NS_ :

BS_:

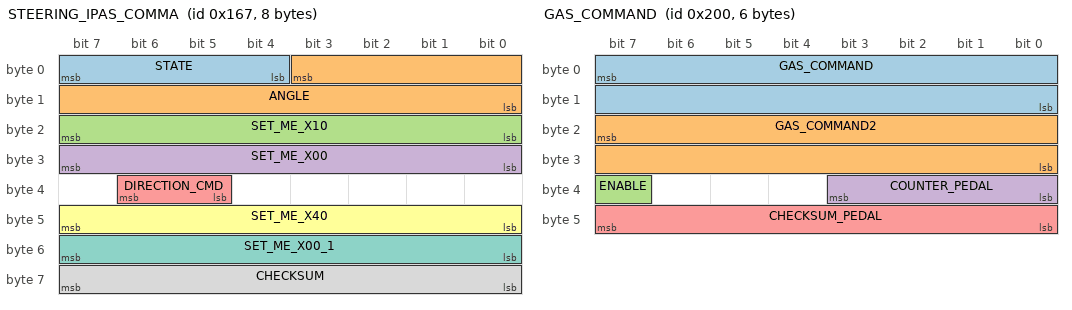
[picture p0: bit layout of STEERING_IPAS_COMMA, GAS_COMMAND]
BO_ 359 STEERING_IPAS_COMMA: 8 IPAS
 SG_ STATE : 7|4@0+ (1,0) [0|15] "" XXX
 SG_ ANGLE : 3|12@0- (1.5,0) [-510|510] "deg" XXX
 SG_ SET_ME_X10 : 23|8@0+ (1,0) [0|255] "" XXX
 SG_ SET_ME_X00 : 31|8@0+ (1,0) [0|255] "" XXX
 SG_ DIRECTION_CMD : 38|2@0+ (1,0) [0|3] "" XXX
 SG_ SET_ME_X40 : 47|8@0+ (1,0) [0|255] "" XXX
 SG_ SET_ME_X00_1 : 55|8@0+ (1,0) [0|255] "" XXX
 SG_ CHECKSUM : 63|8@0+ (1,0) [0|255] "" XXX

BO_ 512 GAS_COMMAND: 6 EON
 SG_ GAS_COMMAND : 7|16@0+ (0.159375,-75.555) [0|1] "" INTERCEPTOR
 SG_ GAS_COMMAND2 : 23|16@0+ (0.159375,-151.111) [0|1] "" INTERCEPTOR
 SG_ ENABLE : 39|1@0+ (1,0) [0|1] "" INTERCEPTOR
 SG_ COUNTER_PEDAL : 35|4@0+ (1,0) [0|15] "" INTERCEPTOR
 SG_ CHECKSUM_PEDAL : 47|8@0+ (1,0) [0|255] "" INTERCEPTOR

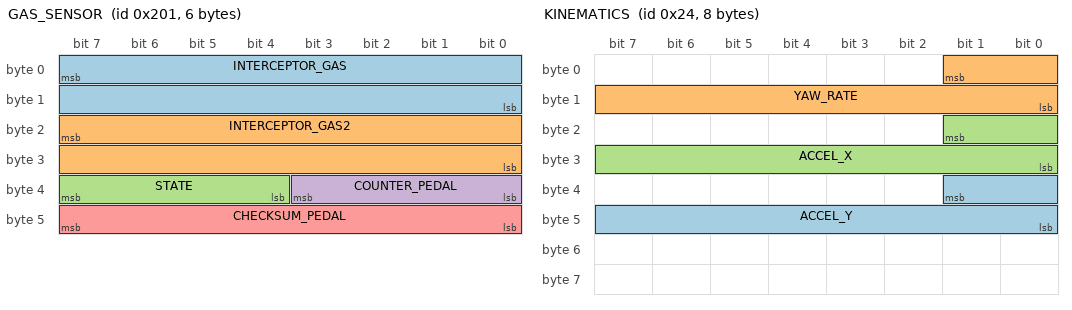
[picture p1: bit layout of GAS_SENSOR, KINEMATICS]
BO_ 513 GAS_SENSOR: 6 INTERCEPTOR
 SG_ INTERCEPTOR_GAS : 7|16@0+ (1,0) [0|1] "" EON
 SG_ INTERCEPTOR_GAS2 : 23|16@0+ (1,0) [0|1] "" EON
 SG_ STATE : 39|4@0+ (1,0) [0|15] "" EON
 SG_ COUNTER_PEDAL : 35|4@0+ (1,0) [0|15] "" EON
 SG_ CHECKSUM_PEDAL : 47|8@0+ (1,0) [0|255] "" EON

BO_ 35 SECONDARY_STEER_ANGLE: 8 XXX
 SG_ ZORRO_STEER : 7|24@0- (0.004901594652,0) [-500|500] "" XXX

BO_ 767 SDSU: 8 XXX
 SG_ FD_BUTTON : 7|1@0+ (1,0) [0|1] "" XXX

BO_ 36 KINEMATICS: 8 XXX
 SG_ ACCEL_Y : 33|10@0+ (0.03589,-18.375) [0|65535] "m/s^2" XXX
 SG_ YAW_RATE : 1|10@0+ (0.244,-125) [0|65535] "deg/s" XXX
 SG_ ACCEL_X : 17|10@0+ (0.03589,-18.375) [0|65535] "m/s^2" XXX

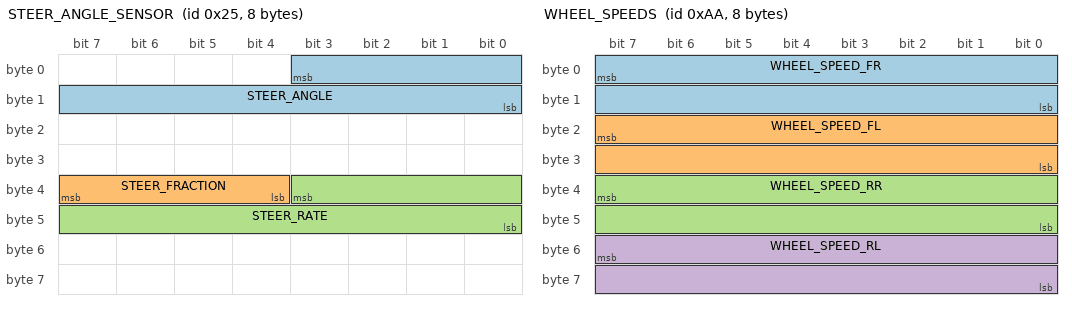
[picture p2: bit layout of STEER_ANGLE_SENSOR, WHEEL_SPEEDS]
BO_ 37 STEER_ANGLE_SENSOR: 8 XXX
 SG_ STEER_ANGLE : 3|12@0- (1.5,0) [-500|500] "deg" XXX
 SG_ STEER_FRACTION : 39|4@0- (0.1,0) [-0.7|0.7] "deg" XXX
 SG_ STEER_RATE : 35|12@0- (1,0) [-2000|2000] "deg/s" XXX

BO_ 166 BRAKE: 8 XXX
 SG_ BRAKE_AMOUNT : 7|8@0+ (1,0) [0|255] "" XXX
 SG_ BRAKE_PEDAL : 23|8@0+ (1,0) [0|255] "" XXX

BO_ 170 WHEEL_SPEEDS: 8 XXX
 SG_ WHEEL_SPEED_FR : 7|16@0+ (0.01,-67.67) [0|250] "km/h" XXX
 SG_ WHEEL_SPEED_FL : 23|16@0+ (0.01,-67.67) [0|250] "km/h" XXX
 SG_ WHEEL_SPEED_RR : 39|16@0+ (0.01,-67.67) [0|250] "km/h" XXX
 SG_ WHEEL_SPEED_RL : 55|16@0+ (0.01,-67.67) [0|250] "km/h" XXX

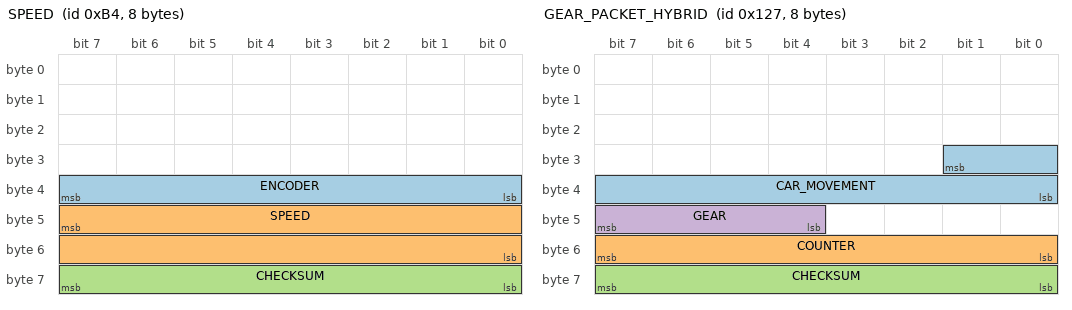
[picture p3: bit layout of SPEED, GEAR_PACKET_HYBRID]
BO_ 180 SPEED: 8 XXX
 SG_ ENCODER : 39|8@0+ (1,0) [0|255] "" XXX
 SG_ SPEED : 47|16@0+ (0.01,0) [0|250] "km/h" XXX
 SG_ CHECKSUM : 63|8@0+ (1,0) [0|255] "" XXX

BO_ 295 GEAR_PACKET_HYBRID: 8 XXX
 SG_ CAR_MOVEMENT : 25|10@0- (1,0) [0|255] "" XXX
 SG_ COUNTER : 55|8@0+ (1,0) [0|255] "" XXX
 SG_ CHECKSUM : 63|8@0+ (1,0) [0|255] "" XXX
 SG_ GEAR : 47|4@0+ (1,0) [0|15] "" XXX

BO_ 353 DSU_SPEED: 7 XXX
 SG_ FORWARD_SPEED : 15|16@0- (0.00390625,-30) [0|255] "km/h" XXX

BO_ 452 ENGINE_RPM: 8 CGW
 SG_ RPM : 7|16@0- (0.78125,0) [0|0] "rpm" SCS

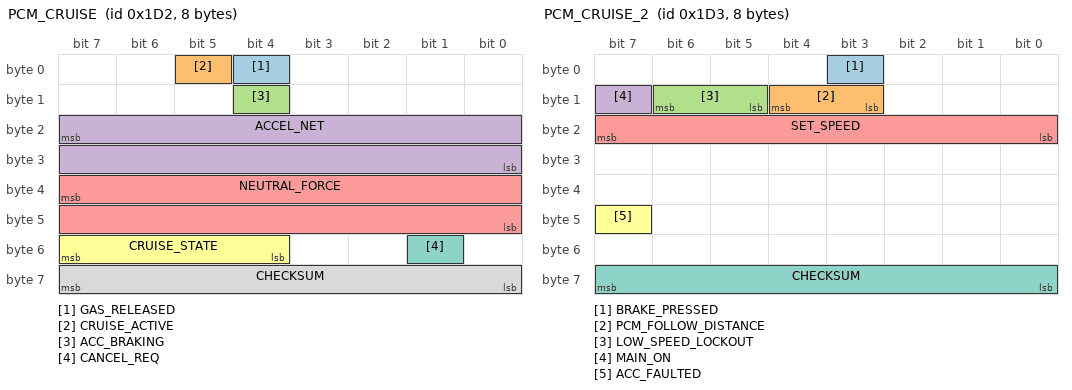
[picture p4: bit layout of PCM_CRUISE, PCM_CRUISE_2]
BO_ 466 PCM_CRUISE: 8 XXX
 SG_ GAS_RELEASED : 4|1@0+ (1,0) [0|1] "" XXX
 SG_ CRUISE_ACTIVE : 5|1@0+ (1,0) [0|1] "" XXX
 SG_ ACC_BRAKING : 12|1@0+ (1,0) [0|1] "" XXX
 SG_ ACCEL_NET : 23|16@0- (0.0009765625,0) [-20|20] "m/s^2" XXX
 SG_ NEUTRAL_FORCE : 39|16@0- (2,0) [-65536|65534] "N" XXX
 SG_ CRUISE_STATE : 55|4@0+ (1,0) [0|15] "" XXX
 SG_ CANCEL_REQ : 49|1@1+ (1,0) [0|1] "" XXX
 SG_ CHECKSUM : 63|8@0+ (1,0) [0|255] "" XXX

BO_ 467 PCM_CRUISE_2: 8 XXX
 SG_ BRAKE_PRESSED : 3|1@0+ (1,0) [0|1] "" XXX
 SG_ PCM_FOLLOW_DISTANCE : 12|2@0+ (1,0) [0|3] "" XXX
 SG_ LOW_SPEED_LOCKOUT : 14|2@0+ (1,0) [0|3] "" XXX
 SG_ MAIN_ON : 15|1@0+ (1,0) [0|1] "" XXX
 SG_ SET_SPEED : 23|8@0+ (1,0) [0|255] "km/h" XXX
 SG_ ACC_FAULTED : 47|1@0+ (1,0) [0|1] "" XXX
 SG_ CHECKSUM : 63|8@0+ (1,0) [0|255] "" XXX

BO_ 552 ACCELEROMETER: 8 XXX
 SG_ ACCEL_Z : 22|15@0- (1,0) [0|32767] "m/s^2" XXX
 SG_ ACCEL_X : 6|15@0- (0.001,0) [-20|20] "m/s^2" XXX

BO_ 560 BRAKE_2: 7 XXX
 SG_ BRAKE_PRESSED : 26|1@0+ (1,0) [0|1] "" XXX

BO_ 581 GAS_PEDAL_HYBRID: 8 XXX
 SG_ GAS_PEDAL : 23|8@0+ (0.005,0) [0|1] "" XXX

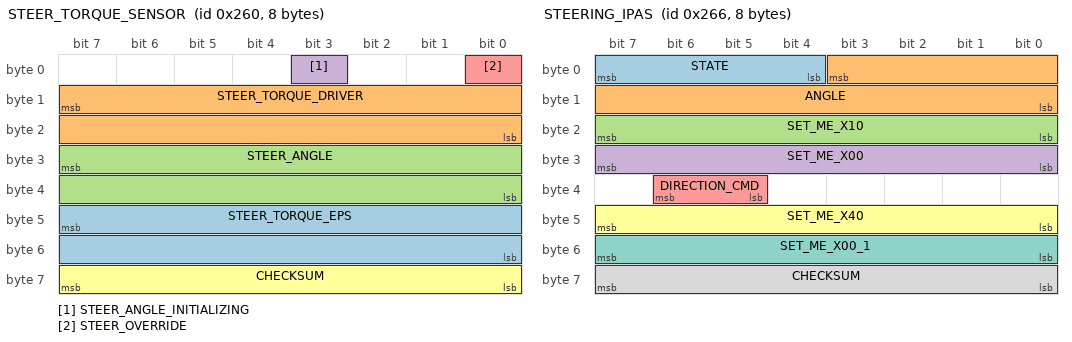
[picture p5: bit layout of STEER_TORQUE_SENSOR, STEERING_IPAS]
BO_ 608 STEER_TORQUE_SENSOR: 8 XXX
 SG_ STEER_TORQUE_EPS : 47|16@0- (1,0) [-32768|32767] "" XXX
 SG_ STEER_TORQUE_DRIVER : 15|16@0- (1,0) [-32768|32767] "" XXX
 SG_ STEER_ANGLE : 31|16@0- (0.0573,0) [-500|500] "" XXX
 SG_ STEER_ANGLE_INITIALIZING : 3|1@0+ (1,0) [0|1] "" XXX
 SG_ STEER_OVERRIDE : 0|1@0+ (1,0) [0|1] "" XXX
 SG_ CHECKSUM : 63|8@0+ (1,0) [0|255] "" XXX

BO_ 614 STEERING_IPAS: 8 IPAS
 SG_ STATE : 7|4@0+ (1,0) [0|15] "" XXX
 SG_ ANGLE : 3|12@0- (1.5,0) [-510|510] "deg" XXX
 SG_ SET_ME_X10 : 23|8@0+ (1,0) [0|255] "" XXX
 SG_ SET_ME_X00 : 31|8@0+ (1,0) [0|255] "" XXX
 SG_ DIRECTION_CMD : 38|2@0+ (1,0) [0|3] "" XXX
 SG_ SET_ME_X40 : 47|8@0+ (1,0) [0|255] "" XXX
 SG_ SET_ME_X00_1 : 55|8@0+ (1,0) [0|255] "" XXX
 SG_ CHECKSUM : 63|8@0+ (1,0) [0|255] "" XXX

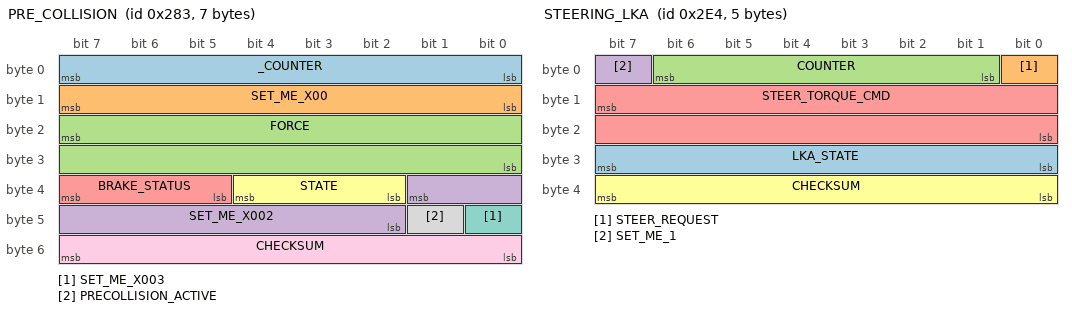
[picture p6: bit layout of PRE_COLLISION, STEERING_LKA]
BO_ 643 PRE_COLLISION: 7 DSU
 SG_ _COUNTER : 7|8@0+ (1,0) [0|255] "" XXX
 SG_ SET_ME_X00 : 15|8@0+ (1,0) [0|255] "" XXX
 SG_ FORCE : 23|16@0- (2,0) [0|255] "N" XXX
 SG_ SET_ME_X002 : 33|8@0+ (1,0) [0|3] "" XXX
 SG_ BRAKE_STATUS : 39|3@0+ (1,0) [0|255] "" XXX
 SG_ STATE : 36|3@0+ (1,0) [0|255] "" XXX
 SG_ SET_ME_X003 : 40|1@0+ (1,0) [0|1] "" XXX
 SG_ PRECOLLISION_ACTIVE : 41|1@0+ (1,0) [0|255] "" XXX
 SG_ CHECKSUM : 55|8@0+ (1,0) [0|255] "" XXX

BO_ 705 GAS_PEDAL: 8 XXX
 SG_ GAS_RELEASED : 3|1@0+ (1,0) [0|1] "" XXX
 SG_ GAS_PEDAL : 55|8@0+ (0.005,0) [0|1] "" XXX

BO_ 740 STEERING_LKA: 5 XXX
 SG_ LKA_STATE : 31|8@0+ (1,0) [0|255] "" XXX
 SG_ STEER_REQUEST : 0|1@0+ (1,0) [0|1] "" XXX
 SG_ COUNTER : 6|6@0+ (1,0) [0|63] "" XXX
 SG_ SET_ME_1 : 7|1@0+ (1,0) [0|1] "" XXX
 SG_ STEER_TORQUE_CMD : 15|16@0- (1,0) [0|65535] "" XXX
 SG_ CHECKSUM : 39|8@0+ (1,0) [0|255] "" XXX

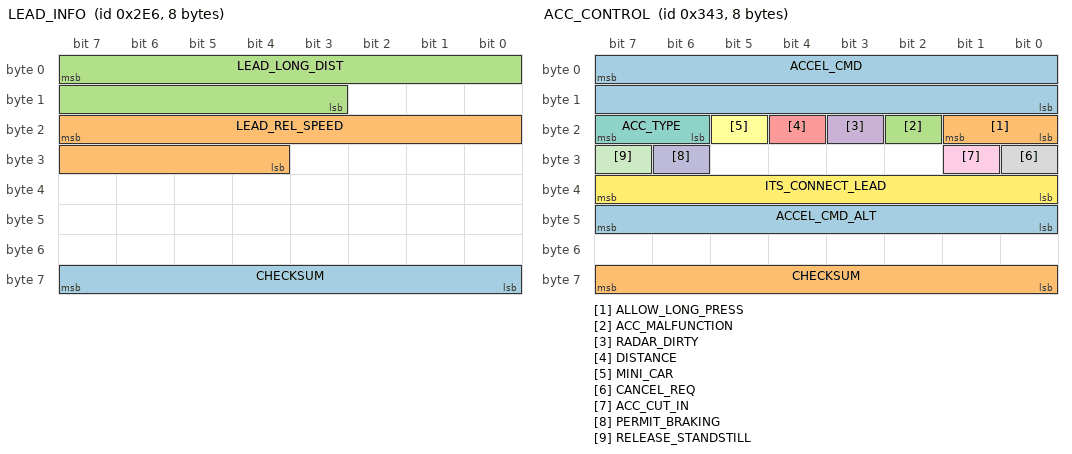
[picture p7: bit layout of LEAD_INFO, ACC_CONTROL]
BO_ 742 LEAD_INFO: 8 DSU
 SG_ CHECKSUM : 63|8@0+ (1,0) [0|255] "" HCU
 SG_ LEAD_REL_SPEED : 23|12@0- (0.025,0) [-100|100] "m/s" HCU
 SG_ LEAD_LONG_DIST : 7|13@0+ (0.05,0) [0|300] "m" HCU

BO_ 835 ACC_CONTROL: 8 DSU
 SG_ ACCEL_CMD : 7|16@0- (0.001,0) [-20|20] "m/s^2" HCU
 SG_ ALLOW_LONG_PRESS : 17|2@0+ (1,0) [0|2] "" XXX
 SG_ ACC_MALFUNCTION : 18|1@0+ (1,0) [0|0] "" XXX
 SG_ RADAR_DIRTY : 19|1@0+ (1,0) [0|1] "" XXX
 SG_ DISTANCE : 20|1@0+ (1,0) [0|1] "" XXX
 SG_ MINI_CAR : 21|1@0+ (1,0) [0|1] "" XXX
 SG_ ACC_TYPE : 23|2@0+ (1,0) [0|3] "" HCU
 SG_ CANCEL_REQ : 24|1@0+ (1,0) [0|1] "" HCU
 SG_ ACC_CUT_IN : 25|1@0+ (1,0) [0|1] "" XXX
 SG_ PERMIT_BRAKING : 30|1@0+ (1,0) [0|1] "" HCU
 SG_ RELEASE_STANDSTILL : 31|1@0+ (1,0) [0|1] "" HCU
 SG_ ITS_CONNECT_LEAD : 39|8@0+ (1,0) [0|1] "" Vector__XXX
 SG_ ACCEL_CMD_ALT : 47|8@0- (0.05,0) [0|0] "m/s^2" XXX
 SG_ CHECKSUM : 63|8@0+ (1,0) [0|255] "" XXX

BO_ 836 PRE_COLLISION_2: 8 DSU
 SG_ CHECKSUM : 63|8@0+ (1,0) [0|0] "" XXX

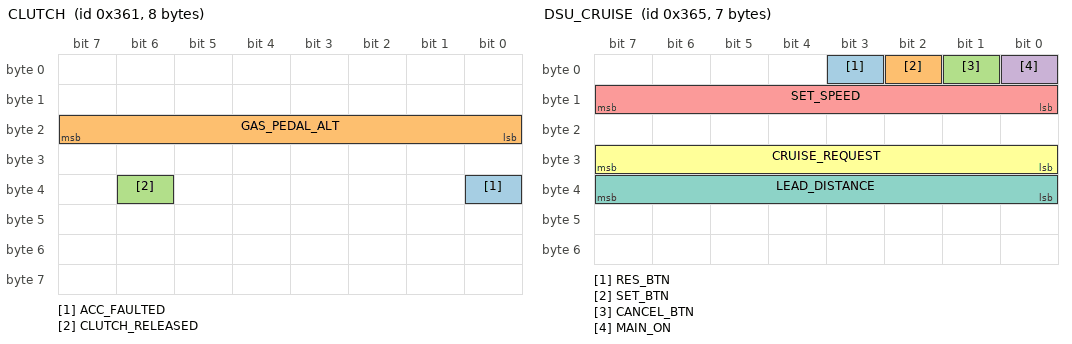
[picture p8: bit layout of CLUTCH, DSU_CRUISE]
BO_ 865 CLUTCH: 8 XXX
 SG_ ACC_FAULTED : 32|1@0+ (1,0) [0|1] "" XXX
 SG_ GAS_PEDAL_ALT : 23|8@0+ (0.005,0) [0|1] "" XXX
 SG_ CLUTCH_RELEASED : 38|1@0+ (1,0) [0|1] "" XXX

BO_ 869 DSU_CRUISE : 7 DSU
 SG_ RES_BTN : 3|1@0+ (1,0) [0|0] "" XXX
 SG_ SET_BTN : 2|1@0+ (1,0) [0|0] "" XXX
 SG_ CANCEL_BTN : 1|1@0+ (1,0) [0|0] "" XXX
 SG_ MAIN_ON : 0|1@0+ (1,0) [0|0] "" XXX
 SG_ SET_SPEED : 15|8@0+ (1,0) [0|0] "km/h" XXX
 SG_ CRUISE_REQUEST : 31|8@0+ (100,-12800) [0|0] "N" XXX
 SG_ LEAD_DISTANCE : 39|8@0+ (1,0) [0|0] "m" XXX

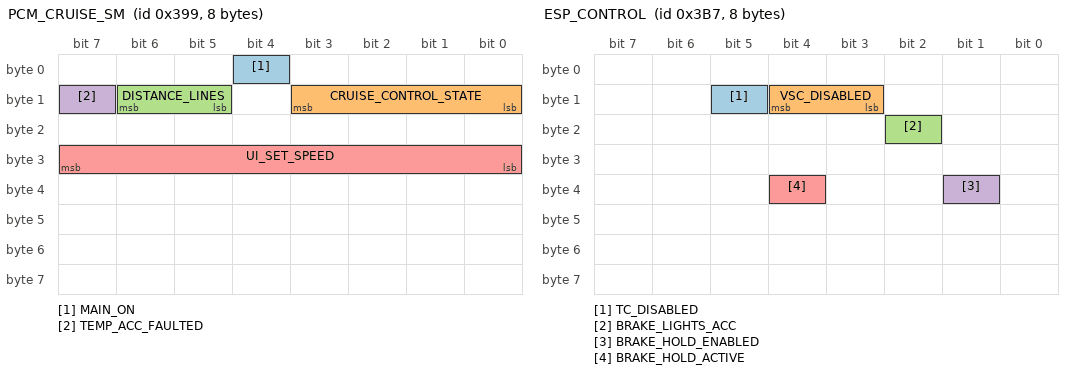
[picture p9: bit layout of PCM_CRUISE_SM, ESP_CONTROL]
BO_ 921 PCM_CRUISE_SM: 8 XXX
 SG_ MAIN_ON : 4|1@0+ (1,0) [0|1] "" XXX
 SG_ CRUISE_CONTROL_STATE : 11|4@0+ (1,0) [0|15] "" XXX
 SG_ DISTANCE_LINES : 14|2@0+ (1,0) [0|3] "" XXX
 SG_ TEMP_ACC_FAULTED : 15|1@0+ (1,0) [0|1] "" XXX
 SG_ UI_SET_SPEED : 31|8@0+ (1,0) [0|255] "" XXX

BO_ 951 ESP_CONTROL: 8 ESP
 SG_ TC_DISABLED : 13|1@0+ (1,0) [0|1] "" XXX
 SG_ VSC_DISABLED : 12|2@0+ (1,0) [0|1] "" XXX
 SG_ BRAKE_LIGHTS_ACC : 18|1@0+ (1,0) [0|1] "" XXX
 SG_ BRAKE_HOLD_ENABLED : 33|1@1+ (1,0) [0|1] "" XXX
 SG_ BRAKE_HOLD_ACTIVE : 36|1@0+ (1,0) [0|1] "" XXX

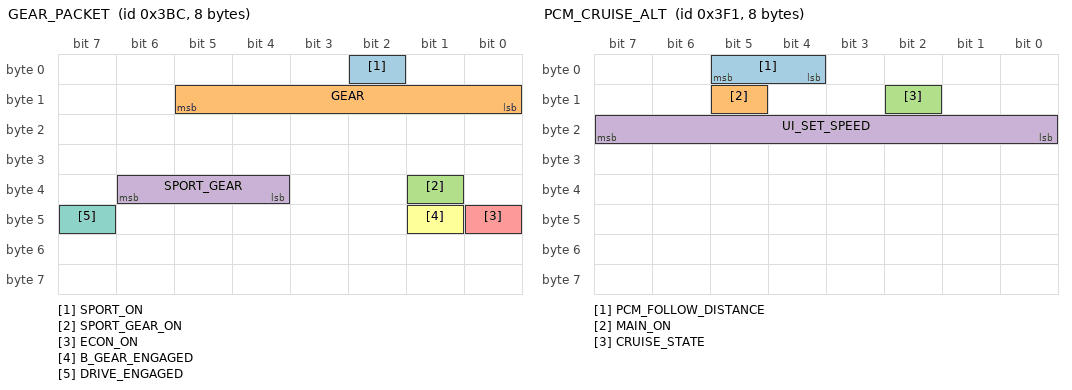
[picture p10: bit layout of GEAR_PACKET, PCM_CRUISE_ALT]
BO_ 956 GEAR_PACKET: 8 XXX
 SG_ SPORT_ON : 2|1@0+ (1,0) [0|1] "" XXX
 SG_ GEAR : 13|6@0+ (1,0) [0|63] "" XXX
 SG_ SPORT_GEAR_ON : 33|1@0+ (1,0) [0|1] "" XXX
 SG_ SPORT_GEAR : 38|3@0+ (1,0) [0|7] "" XXX
 SG_ ECON_ON : 40|1@0+ (1,0) [0|1] "" XXX
 SG_ B_GEAR_ENGAGED : 41|1@0+ (1,0) [0|1] "" XXX
 SG_ DRIVE_ENGAGED : 47|1@0+ (1,0) [0|1] "" XXX

BO_ 1005 REVERSE_CAMERA_STATE: 2 BGM
 SG_ REVERSE_CAMERA_GUIDELINES : 9|2@0+ (1,0) [1|3] "" XXX

BO_ 1009 PCM_CRUISE_ALT: 8 XXX
 SG_ PCM_FOLLOW_DISTANCE : 4|2@1+ (1,0) [0|3] "" XXX
 SG_ MAIN_ON : 13|1@0+ (1,0) [0|3] "" XXX
 SG_ CRUISE_STATE : 10|1@0+ (1,0) [0|1] "" XXX
 SG_ UI_SET_SPEED : 23|8@0+ (1,0) [0|255] "mph" XXX

BO_ 1020 SOLAR_SENSOR: 8 XXX
 SG_ LUX_SENSOR : 55|13@0+ (1,0) [0|0] "" XXX

BO_ 1041 PCS_HUD: 8 DSU
 SG_ PCS_INDICATOR : 7|2@0+ (1,0) [0|3] "" XXX
 SG_ FCW : 4|1@0+ (1,0) [0|1] "" XXX
 SG_ SET_ME_X20 : 15|8@0+ (1,0) [0|1] "" XXX
 SG_ PCS_DUST : 34|1@0+ (1,0) [0|0] "" XXX
 SG_ PCS_TEMP : 35|1@0+ (1,0) [0|0] "" XXX
 SG_ PCS_DUST2 : 41|1@0+ (1,0) [0|0] "" XXX
 SG_ PCS_TEMP2 : 42|1@0+ (1,0) [0|0] "" XXX
 SG_ SET_ME_X10 : 39|8@0+ (1,0) [0|1] "" XXX
 SG_ PCS_OFF : 40|1@0+ (1,0) [0|0] "" XXX
 SG_ FRD_ADJ : 53|3@0+ (1,0) [0|0] "" XXX
 SG_ PCS_SENSITIVITY : 55|8@0+ (1,0) [0|1] "" XXX

BO_ 1042 LKAS_HUD: 8 DSU
 SG_ BARRIERS : 1|2@0+ (1,0) [0|3] "" XXX
 SG_ RIGHT_LINE : 3|2@0+ (1,0) [0|3] "" XXX
 SG_ LEFT_LINE : 5|2@0+ (1,0) [0|3] "" XXX
 SG_ LKAS_STATUS : 7|2@0+ (1,0) [0|3] "" XXX
 SG_ LDA_ALERT : 9|2@0+ (1,0) [0|3] "" XXX
 SG_ LDW_EXIST : 10|1@0+ (1,0) [0|1] "" XXX
 SG_ TWO_BEEPS : 12|1@0+ (1,0) [0|1] "" XXX
 SG_ ADJUSTING_CAMERA : 13|1@0+ (1,0) [0|1] "" XXX
 SG_ LDA_UNAVAILABLE_QUIET : 14|1@0+ (1,0) [0|1] "" XXX
 SG_ LDA_MALFUNCTION : 15|1@0+ (1,0) [0|1] "" XXX
 SG_ LDA_UNAVAILABLE : 16|1@0+ (1,0) [0|1] "" XXX
 SG_ LDA_SENSITIVITY : 18|2@0+ (1,0) [0|3] "" XXX
 SG_ LDA_SA_TOGGLE : 20|2@0+ (1,0) [0|3] "" XXX
 SG_ LDA_MESSAGES : 23|3@0+ (1,0) [0|1] "" XXX
 SG_ LDA_ON_MESSAGE : 31|2@0+ (1,0) [0|3] "" XXX
 SG_ REPEATED_BEEPS : 32|1@0+ (1,0) [0|1] "" XXX
 SG_ LANE_SWAY_TOGGLE : 43|1@0+ (1,0) [0|1] "" XXX
 SG_ LANE_SWAY_SENSITIVITY : 45|2@0+ (1,0) [0|3] "" XXX
 SG_ TAKE_CONTROL : 46|1@0+ (1,0) [0|1] "" XXX
 SG_ LDA_FRONT_CAMERA_BLOCKED : 47|1@0+ (1,0) [0|1] "" XXX
 SG_ LANE_SWAY_BUZZER : 50|2@0+ (1,0) [0|0] "" XXX
 SG_ LANE_SWAY_FLD : 53|3@0+ (1,0) [0|7] "" XXX
 SG_ LANE_SWAY_WARNING : 55|2@0+ (1,0) [0|3] "" XXX
 SG_ SET_ME_X01 : 42|1@0+ (1,0) [0|1] "" XXX
 SG_ SET_ME_X02 : 63|8@0+ (1,0) [0|1] "" XXX

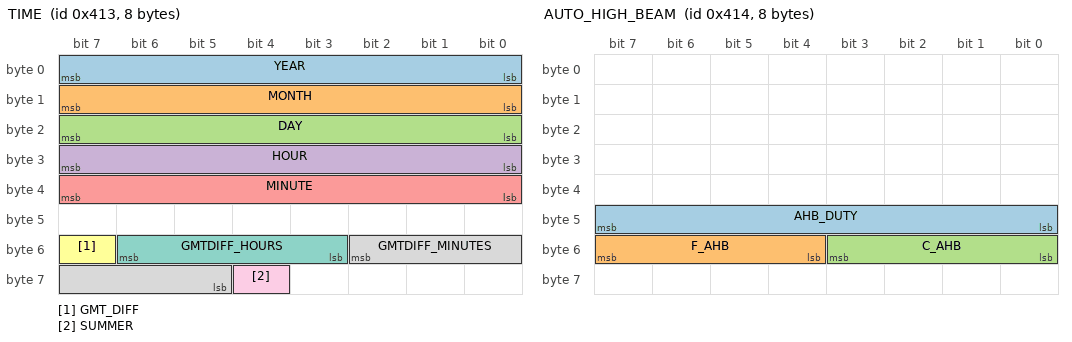
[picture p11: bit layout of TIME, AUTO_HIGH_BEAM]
BO_ 1043 TIME : 8 CGW
 SG_ YEAR : 7|8@0+ (1,0) [0|0] "year" XXX
 SG_ MONTH : 15|8@0+ (1,0) [0|0] "month" XXX
 SG_ DAY : 23|8@0+ (1,0) [0|0] "day" XXX
 SG_ HOUR : 31|8@0+ (1,0) [0|0] "hour" XXX
 SG_ MINUTE : 39|8@0+ (1,0) [0|0] "minute" XXX
 SG_ GMT_DIFF : 55|1@0+ (1,0) [0|0] "" XXX
 SG_ GMTDIFF_HOURS : 54|4@0+ (1,0) [0|0] "hours" XXX
 SG_ GMTDIFF_MINUTES : 50|6@0+ (1,0) [0|0] "minutes" XXX
 SG_ SUMMER : 60|1@0+ (1,0) [0|0] "" XXX

BO_ 1044 AUTO_HIGH_BEAM: 8 FCM
 SG_ AHB_DUTY : 47|8@0+ (0.5,0) [0|0] "%" Vector__XXX
 SG_ F_AHB : 55|4@0+ (1,0) [0|0] "" Vector__XXX
 SG_ C_AHB : 51|4@0+ (1,0) [0|0] "" Vector__XXX

BO_ 1083 AUTOPARK_STATUS: 8 IPAS
 SG_ STATE : 7|4@0+ (1,0) [0|15] "" XXX

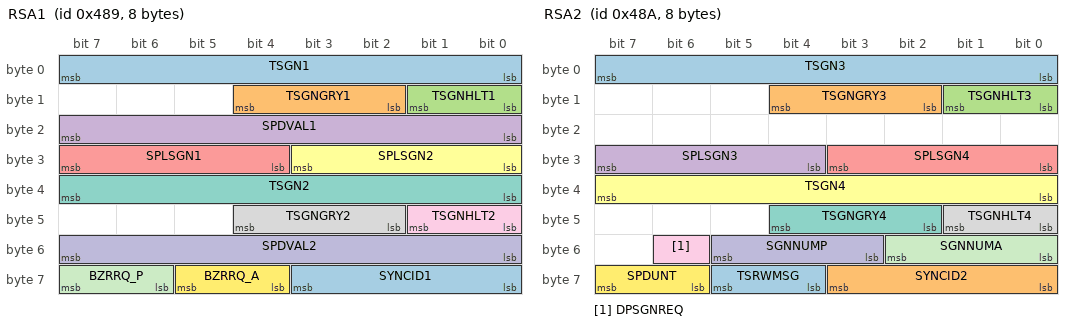
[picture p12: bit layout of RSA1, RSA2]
BO_ 1161 RSA1: 8 FCM
 SG_ TSGN1 : 7|8@0+ (1,0) [0|0] "" XXX
 SG_ TSGNGRY1 : 12|3@0+ (1,0) [0|0] "" XXX
 SG_ TSGNHLT1 : 9|2@0+ (1,0) [0|0] "" XXX
 SG_ SPDVAL1 : 23|8@0+ (1,0) [0|0] "km/h" XXX
 SG_ SPLSGN1 : 31|4@0+ (1,0) [0|0] "" XXX
 SG_ SPLSGN2 : 27|4@0+ (1,0) [0|0] "" XXX
 SG_ TSGN2 : 39|8@0+ (1,0) [0|0] "" XXX
 SG_ TSGNGRY2 : 44|3@0+ (1,0) [0|0] "" XXX
 SG_ TSGNHLT2 : 41|2@0+ (1,0) [0|0] "" XXX
 SG_ SPDVAL2 : 55|8@0+ (1,0) [0|0] "" XXX
 SG_ BZRRQ_P : 63|2@0+ (1,0) [0|0] "" XXX
 SG_ BZRRQ_A : 61|2@0+ (1,0) [0|0] "" XXX
 SG_ SYNCID1 : 59|4@0+ (1,0) [0|0] "" XXX

BO_ 1162 RSA2: 8 FCM
 SG_ TSGN3 : 7|8@0+ (1,0) [0|0] "" XXX
 SG_ TSGNGRY3 : 12|3@0+ (1,0) [0|0] "" XXX
 SG_ TSGNHLT3 : 9|2@0+ (1,0) [0|0] "" XXX
 SG_ SPLSGN3 : 31|4@0+ (1,0) [0|0] "" XXX
 SG_ SPLSGN4 : 27|4@0+ (1,0) [0|0] "" XXX
 SG_ TSGN4 : 39|8@0+ (1,0) [0|0] "" XXX
 SG_ TSGNGRY4 : 44|3@0+ (1,0) [0|0] "" XXX
 SG_ TSGNHLT4 : 41|2@0+ (1,0) [0|0] "" XXX
 SG_ DPSGNREQ : 54|1@0+ (1,0) [0|0] "" XXX
 SG_ SGNNUMP : 53|3@0+ (1,0) [0|0] "" XXX
 SG_ SGNNUMA : 50|3@0+ (1,0) [0|0] "" XXX
 SG_ SPDUNT : 63|2@0+ (1,0) [0|0] "" XXX
 SG_ TSRWMSG : 61|2@0+ (1,0) [0|0] "" XXX
 SG_ SYNCID2 : 59|4@0+ (1,0) [0|0] "" XXX

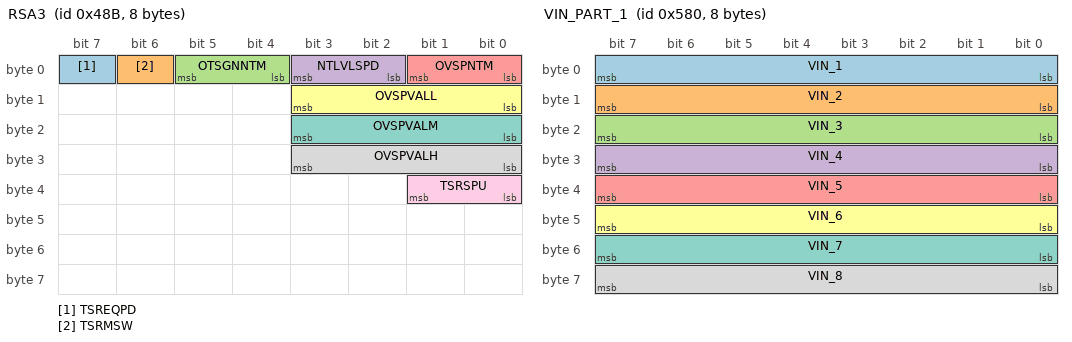
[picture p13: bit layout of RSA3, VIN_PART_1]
BO_ 1163 RSA3: 8 FCM
 SG_ TSREQPD : 7|1@0+ (1,0) [0|0] "" XXX
 SG_ TSRMSW : 6|1@0+ (1,0) [0|0] "" XXX
 SG_ OTSGNNTM : 5|2@0+ (1,0) [0|0] "" XXX
 SG_ NTLVLSPD : 3|2@0+ (1,0) [0|0] "" XXX
 SG_ OVSPNTM : 1|2@0+ (1,0) [0|0] "" XXX
 SG_ OVSPVALL : 11|4@0+ (1,-5) [0|0] "" XXX
 SG_ OVSPVALM : 19|4@0+ (1,-5) [0|0] "" XXX
 SG_ OVSPVALH : 27|4@0+ (1,-5) [0|0] "" XXX
 SG_ TSRSPU : 33|2@0+ (1,0) [0|0] "" XXX

BO_ 1408 VIN_PART_1: 8 CGW
 SG_ VIN_1 : 7|8@0+ (1,0) [0|0] "" XXX
 SG_ VIN_2 : 15|8@0+ (1,0) [0|0] "" XXX
 SG_ VIN_3 : 23|8@0+ (1,0) [0|0] "" XXX
 SG_ VIN_4 : 31|8@0+ (1,0) [0|0] "" XXX
 SG_ VIN_5 : 39|8@0+ (1,0) [0|0] "" XXX
 SG_ VIN_6 : 47|8@0+ (1,0) [0|0] "" XXX
 SG_ VIN_7 : 55|8@0+ (1,0) [0|0] "" XXX
 SG_ VIN_8 : 63|8@0+ (1,0) [0|0] "" XXX

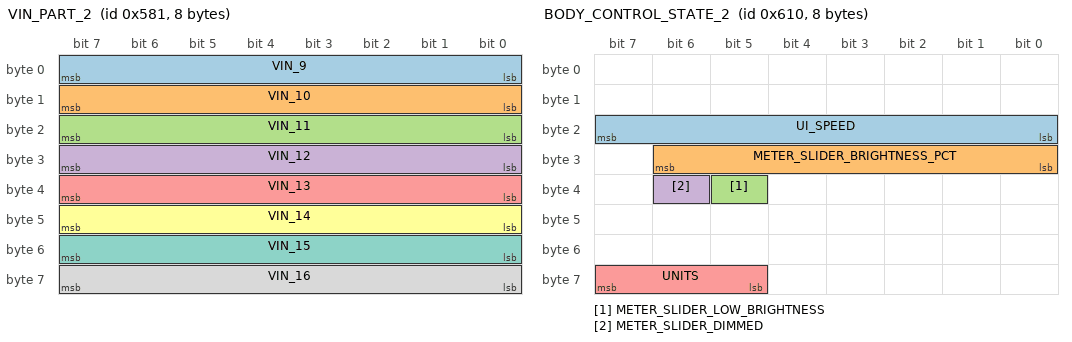
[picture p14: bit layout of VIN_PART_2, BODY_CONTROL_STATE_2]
BO_ 1409 VIN_PART_2: 8 CGW
 SG_ VIN_9 : 7|8@0+ (1,0) [0|0] "" XXX
 SG_ VIN_10 : 15|8@0+ (1,0) [0|0] "" XXX
 SG_ VIN_11 : 23|8@0+ (1,0) [0|0] "" XXX
 SG_ VIN_12 : 31|8@0+ (1,0) [0|0] "" XXX
 SG_ VIN_13 : 39|8@0+ (1,0) [0|0] "" XXX
 SG_ VIN_14 : 47|8@0+ (1,0) [0|0] "" XXX
 SG_ VIN_15 : 55|8@0+ (1,0) [0|0] "" XXX
 SG_ VIN_16 : 63|8@0+ (1,0) [0|0] "" XXX

BO_ 1410 VIN_PART_3: 8 CGW
 SG_ VIN_17 : 7|8@0+ (1,0) [0|0] "" XXX

BO_ 1552 BODY_CONTROL_STATE_2: 8 XXX
 SG_ UI_SPEED : 23|8@0+ (1,0) [0|255] "" XXX
 SG_ METER_SLIDER_BRIGHTNESS_PCT : 30|7@0+ (1,0) [12|100] "%" XXX
 SG_ METER_SLIDER_LOW_BRIGHTNESS : 37|1@0+ (1,0) [0|1] "" XXX
 SG_ METER_SLIDER_DIMMED : 38|1@0+ (1,0) [0|1] "" XXX
 SG_ UNITS : 63|3@0+ (1,0) [1|4] "" XXX

BO_ 1553 UI_SETTING: 8 XXX
 SG_ UNITS : 26|2@0+ (1,0) [0|3] "" XXX
 SG_ ODOMETER : 39|32@0+ (1,0) [0|1048575] "" XXX
BO_ 1556 BLINKERS_STATE: 8 XXX
 SG_ TURN_SIGNALS : 29|2@0+ (1,0) [0|3] "" XXX
 SG_ HAZARD_LIGHT : 27|1@0+ (1,0) [0|1] "" XXX

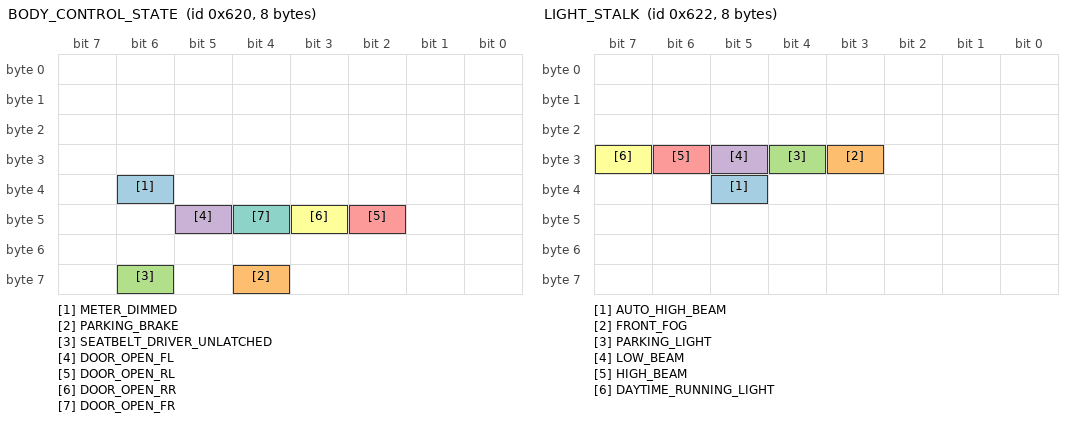
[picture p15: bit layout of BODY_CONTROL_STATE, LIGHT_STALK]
BO_ 1568 BODY_CONTROL_STATE: 8 XXX
 SG_ METER_DIMMED : 38|1@0+ (1,0) [0|1] "" XXX
 SG_ PARKING_BRAKE : 60|1@0+ (1,0) [0|1] "" XXX
 SG_ SEATBELT_DRIVER_UNLATCHED : 62|1@0+ (1,0) [0|1] "" XXX
 SG_ DOOR_OPEN_FL : 45|1@0+ (1,0) [0|1] "" XXX
 SG_ DOOR_OPEN_RL : 42|1@0+ (1,0) [0|1] "" XXX
 SG_ DOOR_OPEN_RR : 43|1@0+ (1,0) [0|1] "" XXX
 SG_ DOOR_OPEN_FR : 44|1@0+ (1,0) [0|1] "" XXX

BO_ 1570 LIGHT_STALK: 8 SCM
 SG_ AUTO_HIGH_BEAM : 37|1@0+ (1,0) [0|1] "" XXX
 SG_ FRONT_FOG : 27|1@0+ (1,0) [0|1] "" XXX
 SG_ PARKING_LIGHT : 28|1@0+ (1,0) [0|1] "" XXX
 SG_ LOW_BEAM : 29|1@0+ (1,0) [0|1] "" XXX
 SG_ HIGH_BEAM : 30|1@0+ (1,0) [0|1] "" XXX
 SG_ DAYTIME_RUNNING_LIGHT : 31|1@0+ (1,0) [0|1] "" XXX

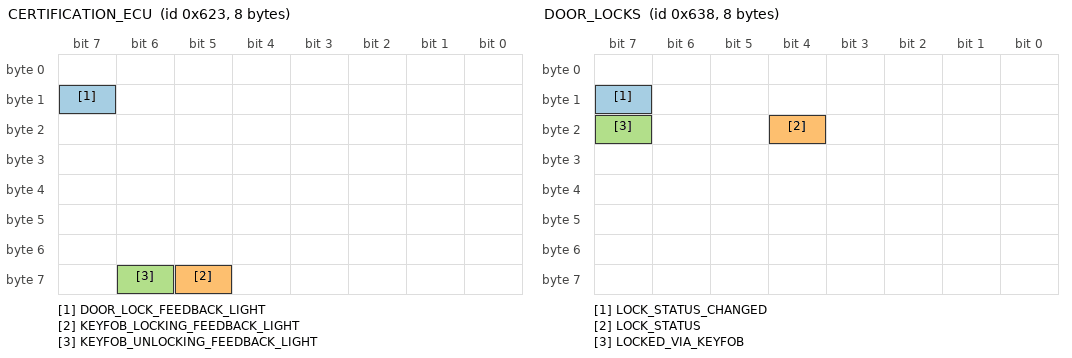
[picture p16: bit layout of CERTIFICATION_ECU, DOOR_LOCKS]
BO_ 1571 CERTIFICATION_ECU: 8 CGW
 SG_ DOOR_LOCK_FEEDBACK_LIGHT : 15|1@0+ (1,0) [0|0] "" XXX
 SG_ KEYFOB_LOCKING_FEEDBACK_LIGHT : 61|1@0+ (1,0) [0|0] "" XXX
 SG_ KEYFOB_UNLOCKING_FEEDBACK_LIGHT : 62|1@0+ (1,0) [0|0] "" XXX

BO_ 1592 DOOR_LOCKS: 8 XXX
 SG_ LOCK_STATUS_CHANGED : 15|1@0+ (1,0) [0|1] "" XXX
 SG_ LOCK_STATUS : 20|1@0+ (1,0) [0|1] "" XXX
 SG_ LOCKED_VIA_KEYFOB : 23|1@0+ (1,0) [0|1] "" XXX

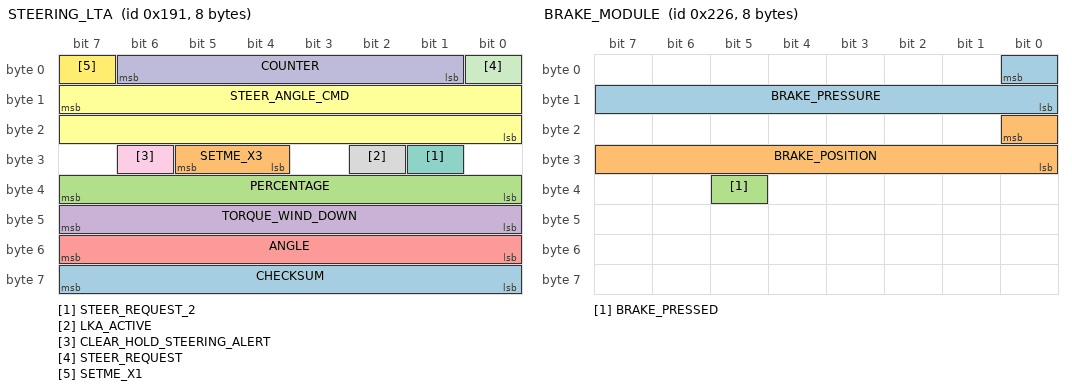
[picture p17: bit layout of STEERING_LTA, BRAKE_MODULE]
BO_ 401 STEERING_LTA: 8 XXX
 SG_ CHECKSUM : 63|8@0+ (1,0) [0|255] "" XXX
 SG_ SETME_X3 : 29|2@0+ (1,0) [0|3] "" XXX
 SG_ PERCENTAGE : 39|8@0+ (1,0) [0|255] "" XXX
 SG_ TORQUE_WIND_DOWN : 47|8@0+ (1,0) [0|255] "" XXX
 SG_ ANGLE : 55|8@0- (0.5,0) [0|255] "" XXX
 SG_ STEER_ANGLE_CMD : 15|16@0- (0.0573,0) [-540|540] "" XXX
 SG_ STEER_REQUEST_2 : 25|1@0+ (1,0) [0|1] "" XXX
 SG_ LKA_ACTIVE : 26|1@0+ (1,0) [0|1] "" XXX
 SG_ CLEAR_HOLD_STEERING_ALERT : 30|1@0+ (1,0) [0|1] "" XXX
 SG_ COUNTER : 6|6@0+ (1,0) [0|255] "" XXX
 SG_ STEER_REQUEST : 0|1@0+ (1,0) [0|1] "" XXX
 SG_ SETME_X1 : 7|1@0+ (1,0) [0|1] "" XXX

BO_ 550 BRAKE_MODULE: 8 XXX
 SG_ BRAKE_PRESSURE : 0|9@0+ (1,0) [0|511] "" XXX
 SG_ BRAKE_POSITION : 16|9@0+ (1,0) [0|511] "" XXX
 SG_ BRAKE_PRESSED : 37|1@0+ (1,0) [0|1] "" XXX

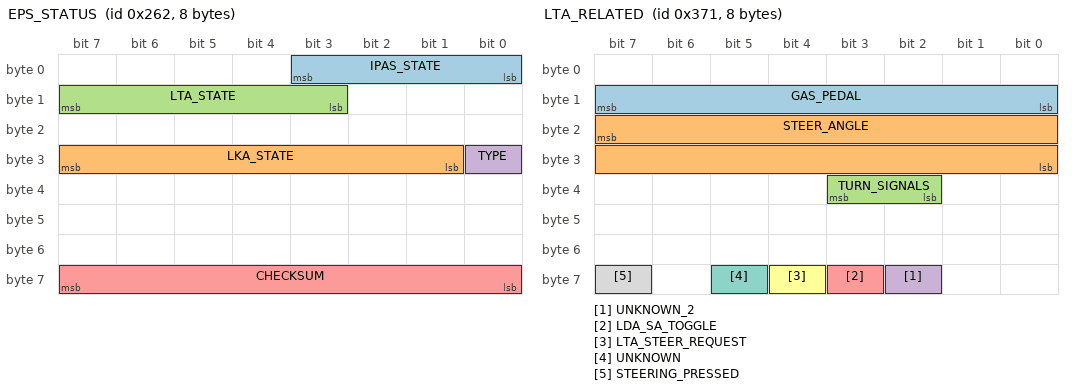
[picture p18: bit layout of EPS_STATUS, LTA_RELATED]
BO_ 610 EPS_STATUS: 8 EPS
 SG_ IPAS_STATE : 3|4@0+ (1,0) [0|15] "" XXX
 SG_ LKA_STATE : 31|7@0+ (1,0) [0|127] "" XXX
 SG_ LTA_STATE : 15|5@0+ (1,0) [0|31] "" XXX
 SG_ TYPE : 24|1@0+ (1,0) [0|1] "" XXX
 SG_ CHECKSUM : 63|8@0+ (1,0) [0|255] "" XXX

BO_ 881 LTA_RELATED: 8 FCM
 SG_ GAS_PEDAL : 15|8@0+ (0.005,0) [0|1] "" XXX
 SG_ STEER_ANGLE : 23|16@0- (0.0573,0) [-500|500] "" XXX
 SG_ TURN_SIGNALS : 35|2@0+ (1,0) [0|3] "" XXX
 SG_ UNKNOWN_2 : 58|1@0+ (1,0) [0|1] "" XXX
 SG_ LDA_SA_TOGGLE : 59|1@0+ (1,0) [0|1] "" XXX
 SG_ LTA_STEER_REQUEST : 60|1@0+ (1,0) [0|1] "" XXX
 SG_ UNKNOWN : 61|1@0+ (1,0) [0|1] "" XXX
 SG_ STEERING_PRESSED : 63|1@0+ (1,0) [0|1] "" XXX

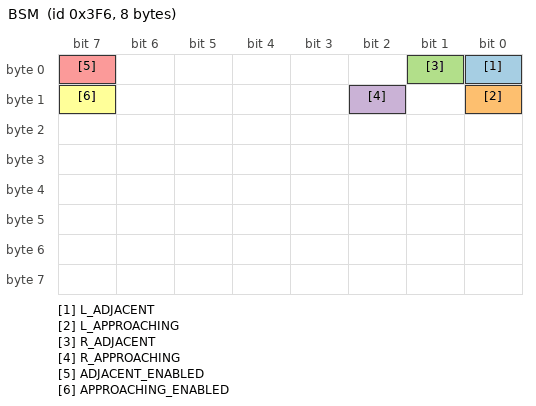
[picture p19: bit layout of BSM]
BO_ 1014 BSM: 8 XXX
 SG_ L_ADJACENT : 0|1@0+ (1,0) [0|1] "" XXX
 SG_ L_APPROACHING : 8|1@0+ (1,0) [0|1] "" XXX
 SG_ R_ADJACENT : 1|1@0+ (1,0) [0|1] "" XXX
 SG_ R_APPROACHING : 10|1@0+ (1,0) [0|1] "" XXX
 SG_ ADJACENT_ENABLED : 7|1@0+ (1,0) [0|1] "" XXX
 SG_ APPROACHING_ENABLED : 15|1@0+ (1,0) [0|1] "" XXX

BU_: XXX

CM_ "AUTOGENERATED FILE, DO NOT EDIT";

CM_ "Imported file _nissan_common.dbc starts here";
CM_ "nissan_x_trail_2017.dbc starts here";

VAL_ 513 STATE 5 "FAULT_TIMEOUT" 4 "FAULT_STARTUP" 3 "FAULT_SCE" 2 "FAULT_SEND" 1 "FAULT_BAD_CHECKSUM" 0 "NO_FAULT" ;

VAL_ 295 GEAR 0 "P" 1 "R" 2 "N" 3 "D" 4 "B";
VAL_ 466 CRUISE_STATE 11 "timer_3sec" 10 "adaptive click down" 9 "adaptive click up" 8 "adaptive engaged" 7 "standstill" 6 "non-adaptive click up" 5 "non-adaptive click down" 4 "non-adaptive hold down" 3 "non-adaptive hold up" 2 "non-adaptive being engaged" 1 "non-adaptive engaged" 0 "off";
VAL_ 467 LOW_SPEED_LOCKOUT 2 "low speed locked" 1 "ok";
VAL_ 467 PCM_FOLLOW_DISTANCE 1 "far" 2 "medium" 3 "close";
VAL_ 614 STATE 3 "enabled" 1 "disabled";
VAL_ 614 DIRECTION_CMD 3 "right" 2 "center" 1 "left";
VAL_ 643 STATE 0 "normal" 1 "adaptive_cruise_control" 3 "emergency_braking";
VAL_ 835 ACC_TYPE 2 "permanent low speed lockout" 1 "ok";
VAL_ 835 ACC_MALFUNCTION 1 "faulted" 0 "ok";
VAL_ 835 ACC_CUT_IN 1 "CUT-IN Detected" 0 "clear";
VAL_ 835 ALLOW_LONG_PRESS 2 "set speed increase by 5 speed units regardless" 1 "set speed increase by 1 speed unit on short press, 5 speed units on long press";
VAL_ 865 CLUTCH_RELEASED 0 "clutch pressed any amount" 1 "clutch released"
VAL_ 921 CRUISE_CONTROL_STATE 2 "disabled" 11 "hold" 10 "hold_waiting_user_cmd" 6 "enabled" 5 "faulted";
VAL_ 956 SPORT_ON 0 "off" 1 "on";
VAL_ 956 GEAR 0 "D" 1 "S" 8 "N" 16 "R" 32 "P";
VAL_ 956 SPORT_GEAR_ON 0 "off" 1 "on";
VAL_ 956 SPORT_GEAR 1 "S1" 2 "S2" 3 "S3" 4 "S4" 5 "S5" 6 "S6";
VAL_ 956 ECON_ON 0 "off" 1 "on";
VAL_ 956 B_GEAR_ENGAGED 0 "off" 1 "on";
VAL_ 956 DRIVE_ENGAGED 0 "off" 1 "on";
VAL_ 1005 REVERSE_CAMERA_GUIDELINES 3 "No guidelines" 2 "Static guidelines" 1 "Active guidelines";
VAL_ 1009 PCM_FOLLOW_DISTANCE 1 "far" 2 "medium" 3 "close";
VAL_ 1041 PCS_INDICATOR 2 "PCS Faulted" 1 "PCS Turned Off By User" 0 "PCS Enabled";
VAL_ 1041 PCS_SENSITIVITY 64 "high sensitivity"  128 "mid sensitivity" 192 "low sensitivity" 0 "off";
VAL_ 1042 LDA_ALERT 3 "hold with continuous beep" 2 "LDA unavailable" 1 "hold" 0 "none";
VAL_ 1042 BARRIERS 3 "left" 2 "right" 1 "both" 0 "none";
VAL_ 1042 RIGHT_LINE 3 "orange" 2 "faded" 1 "solid" 0 "none";
VAL_ 1042 LKAS_STATUS 1 "on" 0 "off";
VAL_ 1042 LEFT_LINE 3 "orange" 2 "faded" 1 "solid" 0 "none";
VAL_ 1042 LDA_ON_MESSAGE 2 "Lane Departure Alert Turned ON, Steering Assist Inactive" 1 "Lane Departure Alert Turned ON, Steering Assist Active" 0 "clear";
VAL_ 1042 LDA_SA_TOGGLE  2 "steering assist off" 1 "steering assist on";
VAL_ 1042 LDA_SENSITIVITY 2 "standard" 1 "high" 0 "undefined";
VAL_ 1042 LDA_MESSAGES 4 "lda unavailable at this speed" 1 "lda unavailable below approx 50km/h" 0 "ok";
VAL_ 1042 LDA_FRONT_CAMERA_BLOCKED 1 "lda unavailable" 0 "ok";
VAL_ 1042 TAKE_CONTROL 1 "take control" 0 "ok";
VAL_ 1042 LANE_SWAY_WARNING 3 "ok" 2 "orange please take a break" 1 "prompt would you like to take a break" 0 "ok";
VAL_ 1042 LANE_SWAY_BUZZER 3 "ok" 2 "beep twice" 1 "beep twice" 0 "ok";
VAL_ 1161 TSGN1 1 "speed sign" 0 "none";
VAL_ 1161 TSGN2 1 "speed sign" 0 "none";
VAL_ 1161 SPLSGN2 15 "conditional blank" 4 "wet road" 5 "rain" 0 "none";
VAL_ 1162 TSGN3 0 "none" 1 "speed sign" 2 "0 unlimited" 7 "unlimited" 16 "highway" 17 "no highway" 18 "motorway" 19 "no motorway" 20 "in city" 21 "outside city" 22 "pedestrian area" 23 "no pedestrian area" 65 "no overtaking left" 66 "no overtaking right" 67 "overtaking allowed again" 81 "no right turn" 97 "stop" 105 "yield" 113 "stop" 114 "yield us" 129 "no entry" 138 "no entry tss2" 145 "do not enter";
VAL_ 1162 SPLSGN3 15 "conditional blank" 4 "wet road" 5 "rain" 0 "none";
VAL_ 1552 METER_SLIDER_LOW_BRIGHTNESS 1 "Low brightness mode, footwell lights off" 0 "Normal mode, footwell lights on";
VAL_ 1552 METER_SLIDER_DIMMED 1 "Dimmed" 0 "Not Dimmed";
VAL_ 1552 UNITS 1 "km (km/L)" 2 "km (L/100km)" 3 "miles (MPG US)" 4 "miles (MPG Imperial)";
VAL_ 1553 UNITS 1 "km" 2 "miles";
VAL_ 1556 TURN_SIGNALS 3 "none" 2 "right" 1 "left";
VAL_ 1592 LOCK_STATUS 0 "locked" 1 "unlocked";

VAL_ 610 IPAS_STATE 5 "override" 3 "enabled" 1 "disabled";
